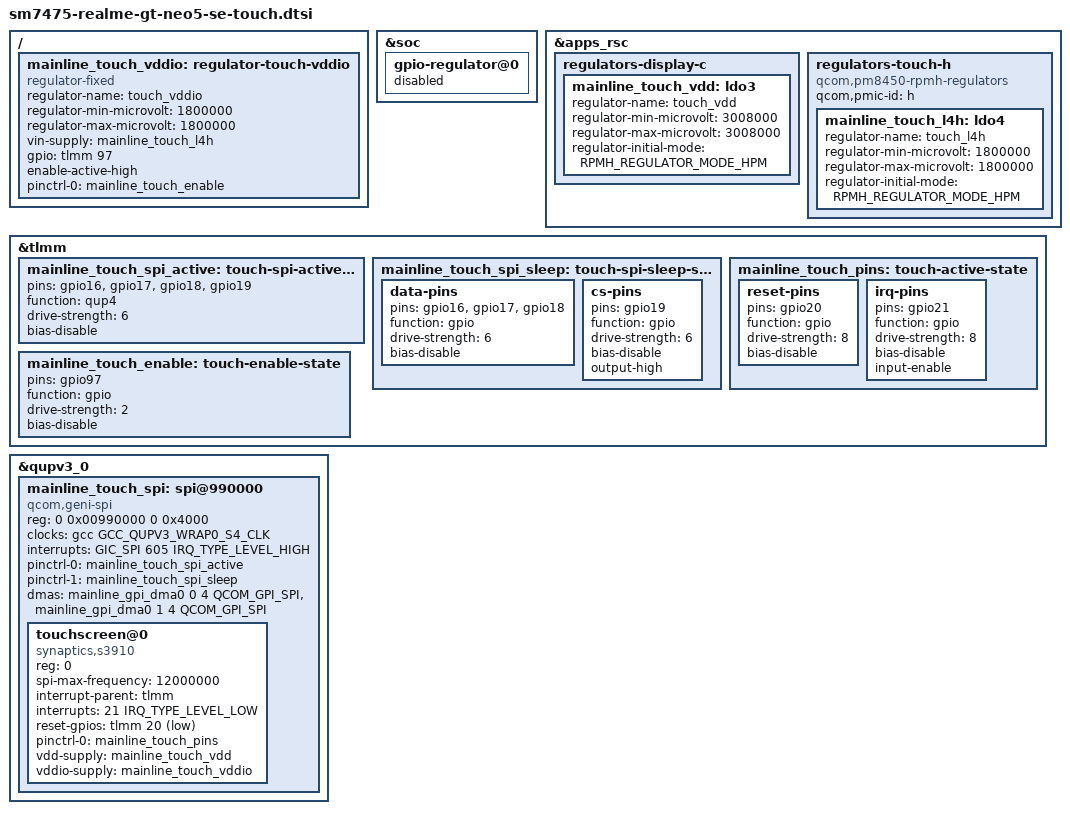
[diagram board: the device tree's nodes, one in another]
// SPDX-License-Identifier: (GPL-2.0-only OR BSD-2-Clause)
/* S3910 wiring and power sequence checked against the Senna stock DT/driver. */
#include <dt-bindings/dma/qcom-gpi.h>

/ {
	mainline_touch_vddio: regulator-touch-vddio {
		compatible = "regulator-fixed";
		regulator-name = "touch_vddio";
		regulator-min-microvolt = <1800000>;
		regulator-max-microvolt = <1800000>;
		vin-supply = <&mainline_touch_l4h>;
		/* The vendor driver ignores the DT flag and drives GPIO97 high. */
		gpio = <&tlmm 97 GPIO_ACTIVE_HIGH>;
		enable-active-high;
		pinctrl-names = "default";
		pinctrl-0 = <&mainline_touch_enable>;
	};
};

&soc {
	/* The stock camera overlay otherwise also requests the touch enable pin.
	 * Its camera driver is not supported by this tree. The overlay does not
	 * set status, so this remains disabled after the bootloader merges it.
	 */
	gpio-regulator@0 {
		status = "disabled";
	};
};

&apps_rsc {
	regulators-display-c {
		mainline_touch_vdd: ldo3 {
			regulator-name = "touch_vdd";
			regulator-min-microvolt = <3008000>;
			regulator-max-microvolt = <3008000>;
			regulator-initial-mode = <RPMH_REGULATOR_MODE_HPM>;
		};
	};

	regulators-touch-h {
		compatible = "qcom,pm8450-rpmh-regulators";
		qcom,pmic-id = "h";

		mainline_touch_l4h: ldo4 {
			regulator-name = "touch_l4h";
			regulator-min-microvolt = <1800000>;
			regulator-max-microvolt = <1800000>;
			regulator-initial-mode = <RPMH_REGULATOR_MODE_HPM>;
		};
	};
};

&tlmm {
	mainline_touch_spi_active: touch-spi-active-state {
		pins = "gpio16", "gpio17", "gpio18", "gpio19";
		function = "qup4";
		drive-strength = <6>;
		bias-disable;
	};

	mainline_touch_spi_sleep: touch-spi-sleep-state {
		data-pins {
			pins = "gpio16", "gpio17", "gpio18";
			function = "gpio";
			drive-strength = <6>;
			bias-disable;
		};
		cs-pins {
			pins = "gpio19";
			function = "gpio";
			drive-strength = <6>;
			bias-disable;
			output-high;
		};
	};

	mainline_touch_pins: touch-active-state {
		reset-pins {
			pins = "gpio20";
			function = "gpio";
			drive-strength = <8>;
			bias-disable;
		};
		irq-pins {
			pins = "gpio21";
			function = "gpio";
			drive-strength = <8>;
			bias-disable;
			input-enable;
		};
	};

	mainline_touch_enable: touch-enable-state {
		pins = "gpio97";
		function = "gpio";
		drive-strength = <2>;
		bias-disable;
	};
};

&qupv3_0 {
	mainline_touch_spi: spi@990000 {
		compatible = "qcom,geni-spi";
		reg = <0 0x00990000 0 0x4000>;
		clocks = <&gcc GCC_QUPV3_WRAP0_S4_CLK>;
		clock-names = "se";
		interrupts = <GIC_SPI 605 IRQ_TYPE_LEVEL_HIGH>;
		pinctrl-names = "default", "sleep";
		pinctrl-0 = <&mainline_touch_spi_active>;
		pinctrl-1 = <&mainline_touch_spi_sleep>;
		dmas = <&mainline_gpi_dma0 0 4 QCOM_GPI_SPI>,
		       <&mainline_gpi_dma0 1 4 QCOM_GPI_SPI>;
		dma-names = "tx", "rx";
		#address-cells = <1>;
		#size-cells = <0>;

		touchscreen@0 {
			compatible = "synaptics,s3910";
			reg = <0>;
			spi-max-frequency = <12000000>;
			interrupt-parent = <&tlmm>;
			interrupts = <21 IRQ_TYPE_LEVEL_LOW>;
			reset-gpios = <&tlmm 20 GPIO_ACTIVE_LOW>;
			pinctrl-names = "default";
			pinctrl-0 = <&mainline_touch_pins>;
			vdd-supply = <&mainline_touch_vdd>;
			vddio-supply = <&mainline_touch_vddio>;
		};
	};
};
